# CEC1736_S0_2HW register map
Vendor: Microchip Technology; Series: CEC; File version: 0
CPU: CM4 r1p0, little endian, MPU, FPU, 3 interrupt priority bits, 196 interrupts
Registers are 32-bit, read-write, reset 0x0 unless marked. A register's access mark holds for its fields unless they carry their own. Offsets are from the block's base; [hi:lo] are bit positions; {n}, {i} and the like mark numbered series; 'fields as' and 'values as' point back to an identical list.

## CCT — This is a 16-bit auto-reloading timer/counter.
Base 0x40001000; register names take the prefix CCT_
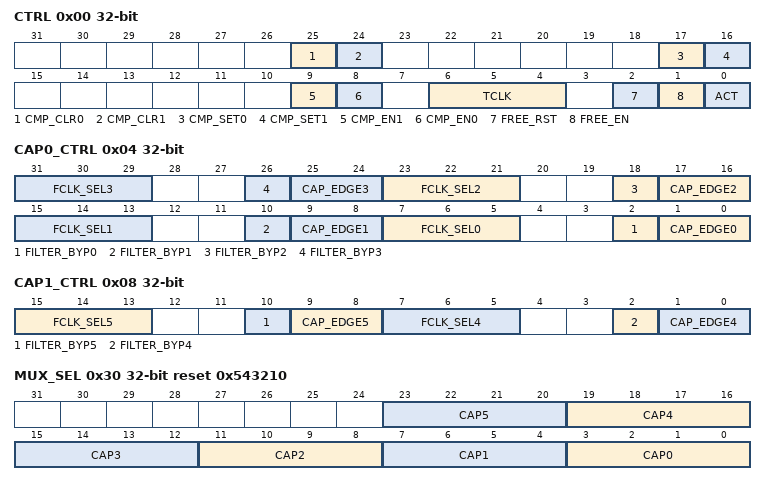
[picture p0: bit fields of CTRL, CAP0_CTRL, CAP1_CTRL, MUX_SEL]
0x00 CTRL — This register controls the capture and compare timer.
  [25] CMP_CLR0 — When read, returns the current value off the Compare Timer Output 0 state.
  [24] CMP_CLR1 — When read, returns the current value off the Compare Timer Output 1 state.
  [17] CMP_SET0 — When read, returns the current value off the Compare Timer Output 0 state.
  [16] CMP_SET1 — When read, returns the current value off the Compare Timer Output 1 state.
  [9] CMP_EN1 — Compare Enable for Compare 1 Register.
  [8] CMP_EN0 — Compare Enable for Compare 0 Register.
  [6:4] TCLK — This 3-bit field sets the clock source for the Free-Running Counter.
  [2] FREE_RST — Free Running Timer Reset. This bit stops the timer and resets the internal counter to 0000_0000h.
  [1] FREE_EN — Free-Running Timer Enable. This bit is used to start and stop the free running timer.
  [0] ACT — This bit is used to start the capture and compare timer running and power it down.
0x04 CAP0_CTRL — This register is used to configure capture and compare timers 0-3.
  [8n+7:8n+5] FCLK_SEL{n} (n=0..3) — This 3-bit field sets the clock source for the input filter for Capture Register {n}.
    0=DIV_1 (Divide by 1 (48 MHz)); 1=DIV_2 (Divide by 2 (24 MHz)); 2=DIV_4 (Divide by 4 (12 MHz)); 3=DIV_8 (Divide by 8 (6 MHz)); 4=DIV_16 (Divide by 16 (3 MHz)); 5=DIV_32 (Divide by 32 (1.5 MHz)); 6=DIV_64 (Divide by 64 (750 KHz)); 7=DIV_128 (Divide by 128 (375 KHz))
  [8n+2] FILTER_BYP{n} (n=0..3) — This bit enables bypassing the input noise filter for Capture Register {n}, so that the input signal goes directly into the timer.
  [8n+1:8n] CAP_EDGE{n} (n=0..3) — This field selects the edge type that triggers the capture of the Free Running Counter into Capture Register {n}.
    0=FALLING (Capture on falling edge); 1=RISING (Capture on rising edge); 2=BOTH (Capture on both falling and rising edges); 3=DISABLED (Capture event disabled)
0x08 CAP1_CTRL — This register is used to configure capture and compare timers 4-5.
  [15:13] FCLK_SEL5 — This 3-bit field sets the clock source for the input filter for Capture Register 5.
    values as CAP0_CTRL.FCLK_SEL0
  [10] FILTER_BYP5 — This bit enables bypassing the input noise filter for Capture Register 5, so that the input signal goes directly into the timer.
  [9:8] CAP_EDGE5 — This field selects the edge type that triggers the capture of the Free Running Counter into Capture Register 5.
    values as CAP0_CTRL.CAP_EDGE0
  [7:5] FCLK_SEL4 — This 3-bit field sets the clock source for the input filter for Capture Register 4.
    values as CAP0_CTRL.FCLK_SEL0
  [2] FILTER_BYP4 — This bit enables bypassing the input noise filter for Capture Register 4, so that the input signal goes directly into the timer.
  [1:0] CAP_EDGE4 — This field selects the edge type that triggers the capture of the Free Running Counter into Capture Register 4.
    values as CAP0_CTRL.CAP_EDGE0
0x0C FREE_RUN — This register contains the current value of the Free Running Timer.
  [31:0] TMR
0x10 CAP0 — This register saves the value copied from the Free Running timer on a programmed edge of ICT0.
  [31:0] CAP_0
0x14 CAP1 — This register saves the value copied from the Free Running timer on a programmed edge of ICT1.
  [31:0] CAP_1
0x18 CAP2 — This register saves the value copied from the Free Running timer on a programmed edge of ICT0.
  [31:0] CAP_2 — This register saves the value copied from the Free Running timer on a programmed edge of ICT2.
0x1C CAP3 — This register saves the value copied from the Free Running timer on a programmed edge of ICT0.
  [31:0] CAP_3 — This register saves the value copied from the Free Running timer on a programmed edge of ICT3.
0x20 CAP4 — This register saves the value copied from the Free Running timer on a programmed edge of ICT4.
  [31:0] CAP_4
0x24 CAP5 — This register saves the value copied from the Free Running timer on a programmed edge of ICT5.
  [31:0] CAP_5
0x28 COMP0 — A COMPARE 0 interrupt is generated when this register matches the value in the Free Running Timer.
  [31:0] COMP_0
0x2C COMP1 — A COMPARE 1 interrupt is generated when this register matches the value in the Free Running Timer.
  [31:0] COMP_1
0x30 MUX_SEL reset 0x543210 — This register selects the pin mapping to the capture register.
  [4n+3:4n] CAP{n} (n=0..5) — Mux Select for Capture {n} register.

## Notices in the file
Copyright (c) 2023 Microchip Technology Inc.
SPDX-License-Identifier: Apache-2.0
Licensed under the Apache License, Version 2.0 (the "License");
you may not use this file except in compliance with the License.
You may obtain a copy of the License at
http://www.apache.org/licenses/LICENSE-2.0
Unless required by applicable law or agreed to in writing, software
distributed under the License is distributed on an "AS IS" BASIS,
WITHOUT WARRANTIES OR CONDITIONS OF ANY KIND, either express or implied.
See the License for the specific language governing permissions and
limitations under the License.
